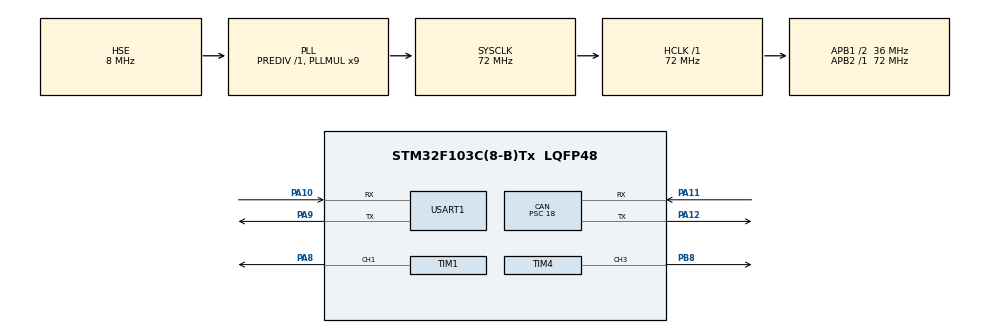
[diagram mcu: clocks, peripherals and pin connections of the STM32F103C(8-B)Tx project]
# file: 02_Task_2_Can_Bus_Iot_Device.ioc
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CAN.BS1=CAN_BS1_13TQ
CAN.BS2=CAN_BS2_2TQ
CAN.CalculateBaudRate=125000
CAN.CalculateTimeBit=8000.00
CAN.CalculateTimeQuantum=500.0
CAN.NART=ENABLE
CAN.Prescaler=18
Mcu.Family=STM32F1
Mcu.Name=STM32F103C(8-B)Tx
Mcu.Package=LQFP48
NVIC.PriorityGroup=NVIC_PRIORITYGROUP_4
PA10.Mode=Asynchronous
PA10.Signal=USART1_RX
PA11.Mode=CAN_Activate
PA11.Signal=CAN_RX
PA12.Mode=CAN_Activate
PA12.Signal=CAN_TX
PA8.Signal=S_TIM1_CH1
PA9.Mode=Asynchronous
PA9.Signal=USART1_TX
PB8.Signal=S_TIM4_CH3
PD0-OSC_IN.Mode=HSE-External-Oscillator
PD0-OSC_IN.Signal=RCC_OSC_IN
PD1-OSC_OUT.Mode=HSE-External-Oscillator
PD1-OSC_OUT.Signal=RCC_OSC_OUT
ProjectManager.HeapSize=0x200
ProjectManager.StackSize=0x400
ProjectManager.TargetToolchain=MDK-ARM V5.27
RCC.AHBFreq_Value=72000000
RCC.APB1CLKDivider=RCC_HCLK_DIV2
RCC.APB1Freq_Value=36000000
RCC.APB1TimFreq_Value=72000000
RCC.APB2Freq_Value=72000000
RCC.APB2TimFreq_Value=72000000
RCC.HCLKFreq_Value=72000000
RCC.PLLMUL=RCC_PLL_MUL9
RCC.PLLSourceVirtual=RCC_PLLSOURCE_HSE
RCC.SYSCLKFreq_VALUE=72000000
RCC.SYSCLKSource=RCC_SYSCLKSOURCE_PLLCLK
RCC.USBFreq_Value=72000000
SH.S_TIM1_CH1.0=TIM1_CH1,PWM Generation1 CH1
SH.S_TIM4_CH3.0=TIM4_CH3,PWM Generation3 CH3
TIM1.Channel-PWM\ Generation1\ CH1=TIM_CHANNEL_1
TIM1.Period=199
TIM1.Prescaler=3
TIM4.Channel-PWM\ Generation3\ CH3=TIM_CHANNEL_3
TIM4.Period=199
TIM4.Prescaler=3
USART1.VirtualMode=VM_ASYNC
VP_SYS_VS_ND.Mode=No_Debug
VP_TIM1_VS_ClockSourceINT.Mode=Internal
VP_TIM4_VS_ClockSourceINT.Mode=Internal
board=custom

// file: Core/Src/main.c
/* USER CODE BEGIN Header */
/**
  ******************************************************************************
  * @file           : main.c
  * @brief          : Main program body
  ******************************************************************************
  * @attention
  *
  * <h2><center>&copy; Copyright (c) 2021 STMicroelectronics.
  * All rights reserved.</center></h2>
  *
  * This software component is licensed by ST under BSD 3-Clause license,
  * the "License"; You may not use this file except in compliance with the
  * License. You may obtain a copy of the License at:
  *                        opensource.org/licenses/BSD-3-Clause
  *
  ******************************************************************************
  */
/* USER CODE END Header */
#include "main.h"
#include "can.h"
#include "tim.h"
#include "usart.h"
#include "gpio.h"

/* USER CODE BEGIN Includes */
#include "sys.h"

/* USER CODE END Includes */

void SystemClock_Config(void);

int main(void)
{

  /* MCU Configuration--------------------------------------------------------*/

  /* Reset of all peripherals, Initializes the Flash interface and the Systick. */
  HAL_Init();

  /* Configure the system clock */
  SystemClock_Config();

  /* Initialize all configured peripherals */
  MX_GPIO_Init();
  MX_CAN_Init();
  MX_USART1_UART_Init();
  MX_TIM1_Init();
  MX_TIM4_Init();
  /* USER CODE BEGIN 2 */
  sys_boot();
  /* USER CODE END 2 */

  /* Infinite loop */
  while (1)
  {

    /* USER CODE BEGIN 3 */
    sys_run();
  }
  /* USER CODE END 3 */
}

void SystemClock_Config(void)
{
  RCC_OscInitTypeDef RCC_OscInitStruct = {0};
  RCC_ClkInitTypeDef RCC_ClkInitStruct = {0};

  /** Initializes the RCC Oscillators according to the specified parameters
  * in the RCC_OscInitTypeDef structure.
  */
  RCC_OscInitStruct.OscillatorType = RCC_OSCILLATORTYPE_HSE;
  RCC_OscInitStruct.HSEState = RCC_HSE_ON;
  RCC_OscInitStruct.HSEPredivValue = RCC_HSE_PREDIV_DIV1;
  RCC_OscInitStruct.HSIState = RCC_HSI_ON;
  RCC_OscInitStruct.PLL.PLLState = RCC_PLL_ON;
  RCC_OscInitStruct.PLL.PLLSource = RCC_PLLSOURCE_HSE;
  RCC_OscInitStruct.PLL.PLLMUL = RCC_PLL_MUL9;
  if (HAL_RCC_OscConfig(&RCC_OscInitStruct) != HAL_OK)
  {
    Error_Handler();
  }
  /** Initializes the CPU, AHB and APB buses clocks
  */
  RCC_ClkInitStruct.ClockType = RCC_CLOCKTYPE_HCLK|RCC_CLOCKTYPE_SYSCLK
                              |RCC_CLOCKTYPE_PCLK1|RCC_CLOCKTYPE_PCLK2;
  RCC_ClkInitStruct.SYSCLKSource = RCC_SYSCLKSOURCE_PLLCLK;
  RCC_ClkInitStruct.AHBCLKDivider = RCC_SYSCLK_DIV1;
  RCC_ClkInitStruct.APB1CLKDivider = RCC_HCLK_DIV2;
  RCC_ClkInitStruct.APB2CLKDivider = RCC_HCLK_DIV1;

  if (HAL_RCC_ClockConfig(&RCC_ClkInitStruct, FLASH_LATENCY_2) != HAL_OK)
  {
    Error_Handler();
  }
}

void Error_Handler(void)
{
  __disable_irq();
  while (1)
  {
  }
}

/************************ (C) COPYRIGHT STMicroelectronics *****END OF FILE****/
